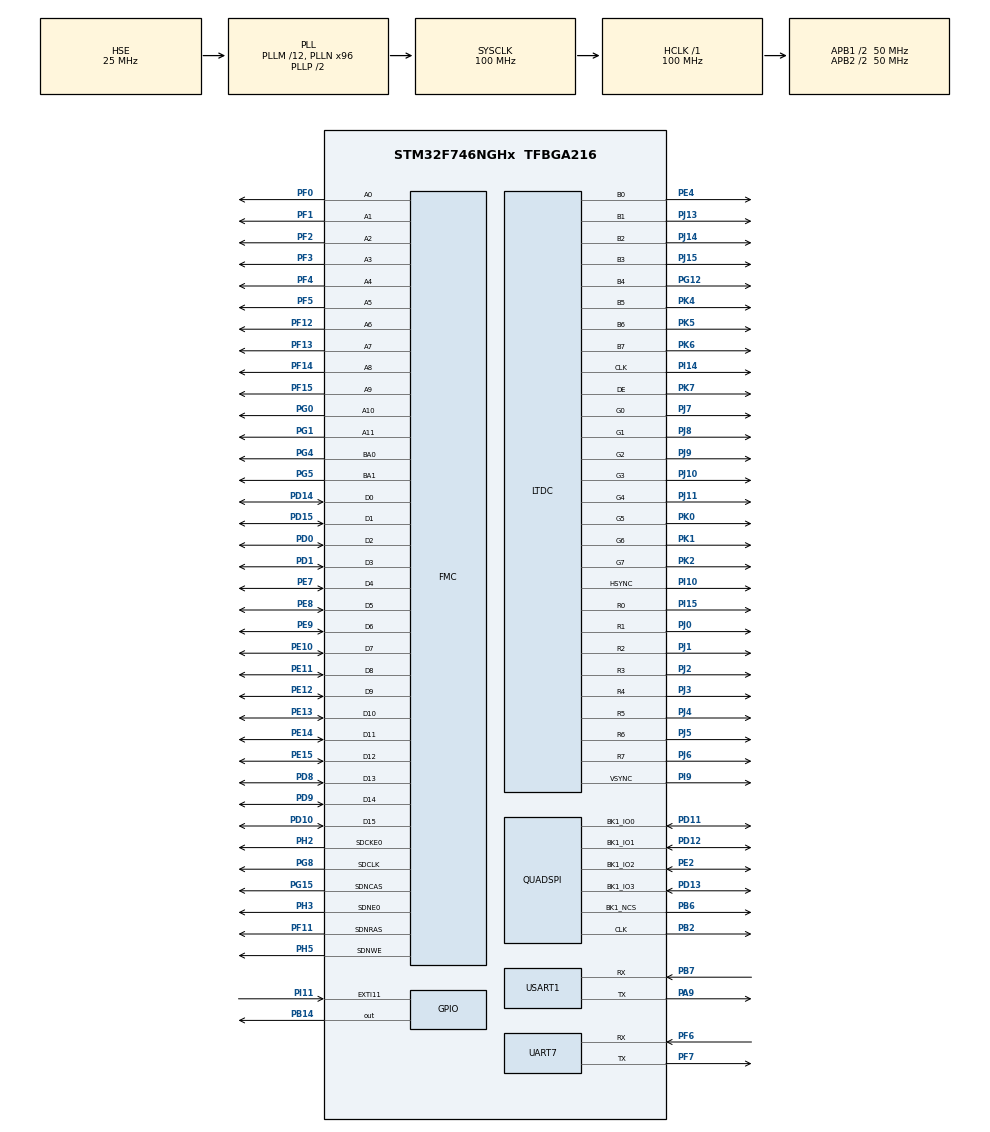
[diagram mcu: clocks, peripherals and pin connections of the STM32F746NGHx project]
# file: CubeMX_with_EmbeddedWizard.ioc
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DMA2D.ColorMode=DMA2D_OUTPUT_RGB565
FMC.CASLatency1=FMC_SDRAM_CAS_LATENCY_3
FMC.ExitSelfRefreshDelay1=7
FMC.LoadToActiveDelay1=2
FMC.RCDDelay1=2
FMC.RPDelay1=2
FMC.RowCycleDelay1=7
FMC.SDClockPeriod1=FMC_SDRAM_CLOCK_PERIOD_2
FMC.SelfRefreshTime1=4
FMC.WriteRecoveryTime1=3
FREERTOS.Queues01=myQueue01,10,uint16_t,0,Dynamic,NULL,NULL
FREERTOS.Tasks01=EwThreadHandle,0,1280,GuiThread,Default,NULL,Dynamic,NULL,NULL;DHT11,0,512,StartTask02,Default,NULL,Dynamic,NULL,NULL
FREERTOS.configTOTAL_HEAP_SIZE=10240
LTDC.ActiveH=272
LTDC.ActiveW=480
LTDC.Alpha_L0=255
LTDC.FBStartAdress_L0=0xC0000000
LTDC.HBP=13
LTDC.HFP=32
LTDC.HSync=41
LTDC.ImageHeight_L0=272
LTDC.ImageWidth_L0=480
LTDC.Layers=0
LTDC.PixelFormat_L0=LTDC_PIXEL_FORMAT_RGB565
LTDC.PixelFormat_L1=LTDC_PIXEL_FORMAT_RGB565
LTDC.VSync=10
LTDC.WindowX1_L0=480
LTDC.WindowY1_L0=272
Mcu.Family=STM32F7
Mcu.Name=STM32F746NGHx
Mcu.Package=TFBGA216
NVIC.DMA2D_IRQn=true\:8\:0\:true\:false\:true\:true\:true\:true
NVIC.EXTI15_10_IRQn=true\:8\:0\:true\:false\:true\:true\:true\:true
NVIC.LTDC_IRQn=true\:8\:0\:true\:false\:true\:true\:true\:true
NVIC.PriorityGroup=NVIC_PRIORITYGROUP_4
NVIC.UART7_IRQn=true\:5\:0\:false\:false\:true\:true\:true\:true
PA9.Mode=Asynchronous
PA9.Signal=USART1_TX
PB14.Signal=GPIO_Output
PB2.Mode=Single Bank 1
PB2.Signal=QUADSPI_CLK
PB6.Mode=Single Bank 1
PB6.Signal=QUADSPI_BK1_NCS
PB7.Mode=Asynchronous
PB7.Signal=USART1_RX
PD0.Signal=FMC_D2_DA2
PD1.Signal=FMC_D3_DA3
PD10.Signal=FMC_D15_DA15
PD11.Mode=Single Bank 1
PD11.Signal=QUADSPI_BK1_IO0
PD12.Mode=Single Bank 1
PD12.Signal=QUADSPI_BK1_IO1
PD13.Mode=Single Bank 1
PD13.Signal=QUADSPI_BK1_IO3
PD14.Signal=FMC_D0_DA0
PD15.Signal=FMC_D1_DA1
PD8.Signal=FMC_D13_DA13
PD9.Signal=FMC_D14_DA14
PE10.Signal=FMC_D7_DA7
PE11.Signal=FMC_D8_DA8
PE12.Signal=FMC_D9_DA9
PE13.Signal=FMC_D10_DA10
PE14.Signal=FMC_D11_DA11
PE15.Signal=FMC_D12_DA12
PE2.Mode=Single Bank 1
PE2.Signal=QUADSPI_BK1_IO2
PE4.GPIO_Speed=GPIO_SPEED_FREQ_VERY_HIGH
PE4.Mode=RGB888
PE4.Signal=LTDC_B0
PE7.Signal=FMC_D4_DA4
PE8.Signal=FMC_D5_DA5
PE9.Signal=FMC_D6_DA6
PF0.Signal=FMC_A0
PF1.Signal=FMC_A1
PF11.Signal=FMC_SDNRAS
PF12.Signal=FMC_A6
PF13.Signal=FMC_A7
PF14.Signal=FMC_A8
PF15.Signal=FMC_A9
PF2.Signal=FMC_A2
PF3.Signal=FMC_A3
PF4.Signal=FMC_A4
PF5.Signal=FMC_A5
PF6.Mode=Asynchronous
PF6.Signal=UART7_RX
PF7.Mode=Asynchronous
PF7.Signal=UART7_TX
PG0.Signal=FMC_A10
PG1.Signal=FMC_A11
PG12.Mode=RGB888
PG12.Signal=LTDC_B4
PG15.Signal=FMC_SDNCAS
PG4.Signal=FMC_A14_BA0
PG5.Signal=FMC_A15_BA1
PG8.Signal=FMC_SDCLK
PH0/OSC_IN.Mode=HSE-External-Oscillator
PH0/OSC_IN.Signal=RCC_OSC_IN
PH1/OSC_OUT.Mode=HSE-External-Oscillator
PH1/OSC_OUT.Signal=RCC_OSC_OUT
PH2.Mode=SdramChipSelect1_1
PH2.Signal=FMC_SDCKE0
PH3.Mode=SdramChipSelect1_1
PH3.Signal=FMC_SDNE0
PH5.Signal=FMC_SDNWE
PI10.Mode=RGB888
PI10.Signal=LTDC_HSYNC
PI11.GPIO_ModeDefaultEXTI=GPIO_MODE_IT_RISING_FALLING
PI11.GPIO_PuPd=GPIO_NOPULL
PI11.Signal=GPXTI11
PI14.Mode=RGB888
PI14.Signal=LTDC_CLK
PI15.Mode=RGB888
PI15.Signal=LTDC_R0
PI9.Mode=RGB888
PI9.Signal=LTDC_VSYNC
PJ0.Mode=RGB888
PJ0.Signal=LTDC_R1
PJ1.Mode=RGB888
PJ1.Signal=LTDC_R2
PJ10.Mode=RGB888
PJ10.Signal=LTDC_G3
PJ11.Mode=RGB888
PJ11.Signal=LTDC_G4
PJ13.Mode=RGB888
PJ13.Signal=LTDC_B1
PJ14.Mode=RGB888
PJ14.Signal=LTDC_B2
PJ15.Mode=RGB888
PJ15.Signal=LTDC_B3
PJ2.Mode=RGB888
PJ2.Signal=LTDC_R3
PJ3.Mode=RGB888
PJ3.Signal=LTDC_R4
PJ4.Mode=RGB888
PJ4.Signal=LTDC_R5
PJ5.Mode=RGB888
PJ5.Signal=LTDC_R6
PJ6.Mode=RGB888
PJ6.Signal=LTDC_R7
PJ7.Mode=RGB888
PJ7.Signal=LTDC_G0
PJ8.Mode=RGB888
PJ8.Signal=LTDC_G1
PJ9.Mode=RGB888
PJ9.Signal=LTDC_G2
PK0.Mode=RGB888
PK0.Signal=LTDC_G5
PK1.Mode=RGB888
PK1.Signal=LTDC_G6
PK2.Mode=RGB888
PK2.Signal=LTDC_G7
PK4.Mode=RGB888
PK4.Signal=LTDC_B5
PK5.Mode=RGB888
PK5.Signal=LTDC_B6
PK6.Mode=RGB888
PK6.Signal=LTDC_B7
PK7.Mode=RGB888
PK7.Signal=LTDC_DE
ProjectManager.HeapSize=0x200
ProjectManager.StackSize=0x400
ProjectManager.TargetToolchain=STM32CubeIDE
RCC.AHBFreq_Value=100000000
RCC.APB1CLKDivider=RCC_HCLK_DIV2
RCC.APB1Freq_Value=50000000
RCC.APB1TimFreq_Value=100000000
RCC.APB2CLKDivider=RCC_HCLK_DIV2
RCC.APB2Freq_Value=50000000
RCC.APB2TimFreq_Value=100000000
RCC.CortexFreq_Value=100000000
RCC.HCLKFreq_Value=100000000
RCC.HSE_VALUE=25000000
RCC.HSI_VALUE=16000000
RCC.LSE_VALUE=32768
RCC.PLL48CLockSelection=RCC_CLK48SOURCE_PLLSAIP
RCC.PLLI2SN=100
RCC.PLLM=12
RCC.PLLN=96
RCC.PLLQ=9
RCC.PLLSAIN=50
RCC.PLLSAIP=RCC_PLLSAIP_DIV8
RCC.PLLSourceVirtual=RCC_PLLSOURCE_HSE
RCC.SDMMCClockSelection=RCC_SDMMC1CLKSOURCE_CLK48
RCC.SYSCLKFreq_VALUE=100000000
RCC.SYSCLKSource=RCC_SYSCLKSOURCE_PLLCLK
RCC.USBFreq_Value=13020833.333333332
RCC.VCOOutputFreq_Value=200000000
SH.FMC_A0.0=FMC_A0,12b-sda1
SH.FMC_A1.0=FMC_A1,12b-sda1
SH.FMC_A10.0=FMC_A10,12b-sda1
SH.FMC_A11.0=FMC_A11,12b-sda1
SH.FMC_A14_BA0.0=FMC_BA0,FourSdramBanks1
SH.FMC_A15_BA1.0=FMC_BA1,FourSdramBanks1
SH.FMC_A2.0=FMC_A2,12b-sda1
SH.FMC_A3.0=FMC_A3,12b-sda1
SH.FMC_A4.0=FMC_A4,12b-sda1
SH.FMC_A5.0=FMC_A5,12b-sda1
SH.FMC_A6.0=FMC_A6,12b-sda1
SH.FMC_A7.0=FMC_A7,12b-sda1
SH.FMC_A8.0=FMC_A8,12b-sda1
SH.FMC_A9.0=FMC_A9,12b-sda1
SH.FMC_D0_DA0.0=FMC_D0,sd-16b-d1
SH.FMC_D10_DA10.0=FMC_D10,sd-16b-d1
SH.FMC_D11_DA11.0=FMC_D11,sd-16b-d1
SH.FMC_D12_DA12.0=FMC_D12,sd-16b-d1
SH.FMC_D13_DA13.0=FMC_D13,sd-16b-d1
SH.FMC_D14_DA14.0=FMC_D14,sd-16b-d1
SH.FMC_D15_DA15.0=FMC_D15,sd-16b-d1
SH.FMC_D1_DA1.0=FMC_D1,sd-16b-d1
SH.FMC_D2_DA2.0=FMC_D2,sd-16b-d1
SH.FMC_D3_DA3.0=FMC_D3,sd-16b-d1
SH.FMC_D4_DA4.0=FMC_D4,sd-16b-d1
SH.FMC_D5_DA5.0=FMC_D5,sd-16b-d1
SH.FMC_D6_DA6.0=FMC_D6,sd-16b-d1
SH.FMC_D7_DA7.0=FMC_D7,sd-16b-d1
SH.FMC_D8_DA8.0=FMC_D8,sd-16b-d1
SH.FMC_D9_DA9.0=FMC_D9,sd-16b-d1
SH.FMC_SDCLK.0=FMC_SDCLK,12b-sda1
SH.FMC_SDNCAS.0=FMC_SDNCAS,12b-sda1
SH.FMC_SDNRAS.0=FMC_SDNRAS,12b-sda1
SH.FMC_SDNWE.0=FMC_SDNWE,12b-sda1
TIM2.Period=3
TIM2.Prescaler=24
USART1.VirtualMode-Asynchronous=VM_ASYNC
VP_DMA2D_VS_DMA2D.Mode=DMA2D_Activate
VP_FREERTOS_VS_CMSIS_V1.Mode=CMSIS_V1
VP_RTC_VS_RTC_Activate.Mode=RTC_Enabled
VP_TIM2_VS_ClockSourceINT.Mode=Internal
board=32F746GDISCOVERY

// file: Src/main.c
#include "main.h"
#include "cmsis_os.h"
#include "DHT11.h"

/* USER CODE BEGIN Includes */
#include "ewmain.h"
#include "ewrte.h"
#include "ew_bsp_console.h"

#include "stm32746g_discovery.h"
#include "stm32746g_discovery_sdram.h"
#include "stm32746g_discovery_qspi.h"

//#include "ModbusRTU.c"
/* USER CODE END Includes */

/* USER CODE BEGIN PTD */
extern float tempDHT;
extern float humidDHT;
float temp;
float humid;
extern unsigned int lux;
/* USER CODE END PTD */

DMA2D_HandleTypeDef hdma2d;

LTDC_HandleTypeDef hltdc;

QSPI_HandleTypeDef hqspi;

RTC_HandleTypeDef hrtc;

TIM_HandleTypeDef htim2;

UART_HandleTypeDef huart7;
UART_HandleTypeDef huart1;

SDRAM_HandleTypeDef hsdram1;

osThreadId EwThreadHandleHandle;
osThreadId DHT11Handle;
osMessageQId myQueue01Handle;

void SystemClock_Config(void);
static void MX_GPIO_Init(void);
static void MX_USART1_UART_Init(void);
static void MX_FMC_Init(void);
static void MX_DMA2D_Init(void);
static void MX_RTC_Init(void);
static void MX_LTDC_Init(void);
static void MX_QUADSPI_Init(void);
static void MX_UART7_Init(void);
static void MX_TIM2_Init(void);
static void EW_SDRAM_Init(void);
static void EW_MPU_Init(void);

void GuiThread(void const * argument);
void StartTask02(void const * argument);

int flag_time = 0;
//void timer2_callBack(TIM_HandleTypeDef *htim){
//	if( htim->Instance == TIM2 ){
//		DHT11_init();
//		temp = tempDHT;
//		humid = humidDHT;
//	}
//}

int main(void)
{

  /* MCU Configuration--------------------------------------------------------*/

  /* Reset of all peripherals, Initializes the Flash interface and the Systick. */
  HAL_Init();

  /* Configure the system clock */
  SystemClock_Config();

  /* USER CODE BEGIN SysInit */
  EW_MPU_Init();
  /* USER CODE END SysInit */

  /* Initialize all configured peripherals */
  MX_GPIO_Init();
  MX_USART1_UART_Init();
  MX_FMC_Init();
  MX_DMA2D_Init();
  MX_RTC_Init();
  MX_LTDC_Init();
  MX_QUADSPI_Init();
  MX_UART7_Init();
  MX_TIM2_Init();
 // DHT11_init();
  /* USER CODE BEGIN 2 */
  EW_SDRAM_Init();
//  HAL_TIM_Base_Start_IT(&htim2);
  /* USER CODE END 2 */

  /* Create the queue(s) */
  /* definition and creation of myQueue01 */
  osMessageQDef(myQueue01, 10, uint16_t);
  myQueue01Handle = osMessageCreate(osMessageQ(myQueue01), NULL);

  /* USER CODE BEGIN RTOS_QUEUES */
  #if EW_USE_FREE_RTOS == 1
  EwPrint( "Create UI thread...                          " );
  /* USER CODE END RTOS_QUEUES */

  /* Create the thread(s) */
  /* definition and creation of EwThreadHandle */
  osThreadDef(EwThreadHandle, GuiThread, osPriorityNormal, 0, 1024);
  EwThreadHandleHandle = osThreadCreate(osThread(EwThreadHandle), NULL);
  /* definition and creation of DHT11 */
  osThreadDef(DHT11, StartTask02, osPriorityNormal, 0, 512);
  DHT11Handle = osThreadCreate(osThread(DHT11), NULL);

  /* USER CODE BEGIN RTOS_THREADS */
  EwPrint( "[OK]\n" );
  #endif
  /* USER CODE END RTOS_THREADS */

   /* definition and creation of DHT11 */

  /* Start scheduler */
  osKernelStart();

  /* We should never get here as control is now taken by the scheduler */

  /* Infinite loop */
  while (1)
  {

    /* USER CODE BEGIN 3 */
  }
  #if EW_USE_FREE_RTOS == 1
  /* de-initialize Embedded Wizard application */
  EwDone();

  return 0;
  #endif
  /* USER CODE END 3 */
}

void SystemClock_Config(void)
{
  RCC_OscInitTypeDef RCC_OscInitStruct = {0};
  RCC_ClkInitTypeDef RCC_ClkInitStruct = {0};
  RCC_PeriphCLKInitTypeDef PeriphClkInitStruct = {0};

  /** Configure the main internal regulator output voltage
  */
  __HAL_RCC_PWR_CLK_ENABLE();
  __HAL_PWR_VOLTAGESCALING_CONFIG(PWR_REGULATOR_VOLTAGE_SCALE3);
  /** Initializes the CPU, AHB and APB busses clocks
  */
  RCC_OscInitStruct.OscillatorType = RCC_OSCILLATORTYPE_LSI|RCC_OSCILLATORTYPE_HSE;
  RCC_OscInitStruct.HSEState = RCC_HSE_ON;
  RCC_OscInitStruct.LSIState = RCC_LSI_ON;
  RCC_OscInitStruct.PLL.PLLState = RCC_PLL_ON;
  RCC_OscInitStruct.PLL.PLLSource = RCC_PLLSOURCE_HSE;
  RCC_OscInitStruct.PLL.PLLM = 12;
  RCC_OscInitStruct.PLL.PLLN = 96;
  RCC_OscInitStruct.PLL.PLLP = RCC_PLLP_DIV2;
  RCC_OscInitStruct.PLL.PLLQ = 9;
  if (HAL_RCC_OscConfig(&RCC_OscInitStruct) != HAL_OK)
  {
    Error_Handler();
  }
  /** Activate the Over-Drive mode
  */
  if (HAL_PWREx_EnableOverDrive() != HAL_OK)
  {
    Error_Handler();
  }
  /** Initializes the CPU, AHB and APB busses clocks
  */
  RCC_ClkInitStruct.ClockType = RCC_CLOCKTYPE_HCLK|RCC_CLOCKTYPE_SYSCLK
                              |RCC_CLOCKTYPE_PCLK1|RCC_CLOCKTYPE_PCLK2;
  RCC_ClkInitStruct.SYSCLKSource = RCC_SYSCLKSOURCE_PLLCLK;
  RCC_ClkInitStruct.AHBCLKDivider = RCC_SYSCLK_DIV1;
  RCC_ClkInitStruct.APB1CLKDivider = RCC_HCLK_DIV2;
  RCC_ClkInitStruct.APB2CLKDivider = RCC_HCLK_DIV2;

  if (HAL_RCC_ClockConfig(&RCC_ClkInitStruct, FLASH_LATENCY_3) != HAL_OK)
  {
    Error_Handler();
  }
  PeriphClkInitStruct.PeriphClockSelection = RCC_PERIPHCLK_LTDC|RCC_PERIPHCLK_RTC
                              |RCC_PERIPHCLK_USART1|RCC_PERIPHCLK_UART7;
  PeriphClkInitStruct.PLLSAI.PLLSAIN = 50;
  PeriphClkInitStruct.PLLSAI.PLLSAIR = 2;
  PeriphClkInitStruct.PLLSAI.PLLSAIQ = 2;
  PeriphClkInitStruct.PLLSAI.PLLSAIP = RCC_PLLSAIP_DIV8;
  PeriphClkInitStruct.PLLSAIDivQ = 1;
  PeriphClkInitStruct.PLLSAIDivR = RCC_PLLSAIDIVR_2;
  PeriphClkInitStruct.RTCClockSelection = RCC_RTCCLKSOURCE_LSI;
  PeriphClkInitStruct.Usart1ClockSelection = RCC_USART1CLKSOURCE_PCLK2;
  PeriphClkInitStruct.Uart7ClockSelection = RCC_UART7CLKSOURCE_PCLK1;
  if (HAL_RCCEx_PeriphCLKConfig(&PeriphClkInitStruct) != HAL_OK)
  {
    Error_Handler();
  }
}

static void MX_DMA2D_Init(void)
{

  hdma2d.Instance = DMA2D;
  hdma2d.Init.Mode = DMA2D_M2M;
  hdma2d.Init.ColorMode = DMA2D_OUTPUT_RGB565;
  hdma2d.Init.OutputOffset = 0;
  hdma2d.LayerCfg[1].InputOffset = 0;
  hdma2d.LayerCfg[1].InputColorMode = DMA2D_INPUT_RGB565;
  hdma2d.LayerCfg[1].AlphaMode = DMA2D_NO_MODIF_ALPHA;
  hdma2d.LayerCfg[1].InputAlpha = 0;
  if (HAL_DMA2D_Init(&hdma2d) != HAL_OK)
  {
    Error_Handler();
  }
  if (HAL_DMA2D_ConfigLayer(&hdma2d, 1) != HAL_OK)
  {
    Error_Handler();
  }

}

static void MX_LTDC_Init(void)
{

  /* USER CODE BEGIN LTDC_Init 0 */
//
  /* USER CODE END LTDC_Init 0 */

  LTDC_LayerCfgTypeDef pLayerCfg = {0};

  /* USER CODE BEGIN LTDC_Init 1 */
//
  /* USER CODE END LTDC_Init 1 */
  hltdc.Instance = LTDC;
  hltdc.Init.HSPolarity = LTDC_HSPOLARITY_AL;
  hltdc.Init.VSPolarity = LTDC_VSPOLARITY_AL;
  hltdc.Init.DEPolarity = LTDC_DEPOLARITY_AL;
  hltdc.Init.PCPolarity = LTDC_PCPOLARITY_IPC;
  hltdc.Init.HorizontalSync = 40;
  hltdc.Init.VerticalSync = 9;
  hltdc.Init.AccumulatedHBP = 53;
  hltdc.Init.AccumulatedVBP = 11;
  hltdc.Init.AccumulatedActiveW = 533;
  hltdc.Init.AccumulatedActiveH = 283;
  hltdc.Init.TotalWidth = 565;
  hltdc.Init.TotalHeigh = 285;
  hltdc.Init.Backcolor.Blue = 0;
  hltdc.Init.Backcolor.Green = 0;
  hltdc.Init.Backcolor.Red = 0;
  if (HAL_LTDC_Init(&hltdc) != HAL_OK)
  {
    Error_Handler();
  }
  pLayerCfg.WindowX0 = 0;
  pLayerCfg.WindowX1 = 480;
  pLayerCfg.WindowY0 = 0;
  pLayerCfg.WindowY1 = 272;
  pLayerCfg.PixelFormat = LTDC_PIXEL_FORMAT_RGB565;
  pLayerCfg.Alpha = 255;
  pLayerCfg.Alpha0 = 0;
  pLayerCfg.BlendingFactor1 = LTDC_BLENDING_FACTOR1_CA;
  pLayerCfg.BlendingFactor2 = LTDC_BLENDING_FACTOR2_CA;
  pLayerCfg.FBStartAdress = 0xC0000000;
  pLayerCfg.ImageWidth = 480;
  pLayerCfg.ImageHeight = 272;
  pLayerCfg.Backcolor.Blue = 0;
  pLayerCfg.Backcolor.Green = 0;
  pLayerCfg.Backcolor.Red = 0;
  if (HAL_LTDC_ConfigLayer(&hltdc, &pLayerCfg, 0) != HAL_OK)
  {
    Error_Handler();
  }
  /* USER CODE BEGIN LTDC_Init 2 */
//
  /* USER CODE END LTDC_Init 2 */

}

static void MX_QUADSPI_Init(void)
{

  /* USER CODE BEGIN QUADSPI_Init 0 */
#if EW_USE_EXTERNAL_FLASH == 1
  /* USER CODE END QUADSPI_Init 0 */

  /* QUADSPI parameter configuration*/
  hqspi.Instance = QUADSPI;
  hqspi.Init.ClockPrescaler = 255;
  hqspi.Init.FifoThreshold = 1;
  hqspi.Init.SampleShifting = QSPI_SAMPLE_SHIFTING_NONE;
  hqspi.Init.FlashSize = 1;
  hqspi.Init.ChipSelectHighTime = QSPI_CS_HIGH_TIME_1_CYCLE;
  hqspi.Init.ClockMode = QSPI_CLOCK_MODE_0;
  hqspi.Init.FlashID = QSPI_FLASH_ID_1;
  hqspi.Init.DualFlash = QSPI_DUALFLASH_DISABLE;
  if (HAL_QSPI_Init(&hqspi) != HAL_OK)
  {
    Error_Handler();
  }
  /* USER CODE BEGIN QUADSPI_Init 2 */

  BSP_QSPI_Init();
  BSP_QSPI_EnableMemoryMappedMode();

  /* configure QSPI: LPTR register with the low-power time out value */
  WRITE_REG( QUADSPI->LPTR, 0xFFF );
#endif
  /* USER CODE END QUADSPI_Init 2 */

}

static void MX_RTC_Init(void)
{

  /** Initialize RTC Only
  */
  hrtc.Instance = RTC;
  hrtc.Init.HourFormat = RTC_HOURFORMAT_24;
  hrtc.Init.AsynchPrediv = 127;
  hrtc.Init.SynchPrediv = 255;
  if (HAL_RTC_Init(&hrtc) != HAL_OK)
  {
    Error_Handler();
  }

}

static void MX_TIM2_Init(void)
{

  TIM_ClockConfigTypeDef sClockSourceConfig = {0};
  TIM_MasterConfigTypeDef sMasterConfig = {0};

  htim2.Instance = TIM2;
  htim2.Init.Prescaler = 24;
  htim2.Init.CounterMode = TIM_COUNTERMODE_UP;
  htim2.Init.Period = 3;
  htim2.Init.ClockDivision = TIM_CLOCKDIVISION_DIV1;
  htim2.Init.AutoReloadPreload = TIM_AUTORELOAD_PRELOAD_DISABLE;
  if (HAL_TIM_Base_Init(&htim2) != HAL_OK)
  {
    Error_Handler();
  }
  sClockSourceConfig.ClockSource = TIM_CLOCKSOURCE_INTERNAL;
  if (HAL_TIM_ConfigClockSource(&htim2, &sClockSourceConfig) != HAL_OK)
  {
    Error_Handler();
  }
  sMasterConfig.MasterOutputTrigger = TIM_TRGO_RESET;
  sMasterConfig.MasterSlaveMode = TIM_MASTERSLAVEMODE_DISABLE;
  if (HAL_TIMEx_MasterConfigSynchronization(&htim2, &sMasterConfig) != HAL_OK)
  {
    Error_Handler();
  }
  /* USER CODE BEGIN TIM2_Init 2 */
 // flag_time = 1;
//  __HAL_TIM_CLEAR_FLAG(&htim2, TIM_SR_UIF);
//  HAL_TIM_Base_Start_IT(&htim2);
  /* USER CODE END TIM2_Init 2 */

}

static void MX_UART7_Init(void)
{

  huart7.Instance = UART7;
  huart7.Init.BaudRate = 115200;
  huart7.Init.WordLength = UART_WORDLENGTH_8B;
  huart7.Init.StopBits = UART_STOPBITS_1;
  huart7.Init.Parity = UART_PARITY_NONE;
  huart7.Init.Mode = UART_MODE_TX_RX;
  huart7.Init.HwFlowCtl = UART_HWCONTROL_NONE;
  huart7.Init.OverSampling = UART_OVERSAMPLING_16;
  huart7.Init.OneBitSampling = UART_ONE_BIT_SAMPLE_DISABLE;
  huart7.AdvancedInit.AdvFeatureInit = UART_ADVFEATURE_NO_INIT;
  if (HAL_UART_Init(&huart7) != HAL_OK)
  {
    Error_Handler();
  }

}

static void MX_USART1_UART_Init(void)
{

  huart1.Instance = USART1;
  huart1.Init.BaudRate = 115200;
  huart1.Init.WordLength = UART_WORDLENGTH_8B;
  huart1.Init.StopBits = UART_STOPBITS_1;
  huart1.Init.Parity = UART_PARITY_NONE;
  huart1.Init.Mode = UART_MODE_TX_RX;
  huart1.Init.HwFlowCtl = UART_HWCONTROL_NONE;
  huart1.Init.OverSampling = UART_OVERSAMPLING_16;
  huart1.Init.OneBitSampling = UART_ONE_BIT_SAMPLE_DISABLE;
  huart1.AdvancedInit.AdvFeatureInit = UART_ADVFEATURE_NO_INIT;
  if (HAL_UART_Init(&huart1) != HAL_OK)
  {
    Error_Handler();
  }

}

/* FMC initialization function */
static void MX_FMC_Init(void)
{

  FMC_SDRAM_TimingTypeDef SdramTiming = {0};

  /** Perform the SDRAM1 memory initialization sequence
  */
  hsdram1.Instance = FMC_SDRAM_DEVICE;
  /* hsdram1.Init */
  hsdram1.Init.SDBank = FMC_SDRAM_BANK1;
  hsdram1.Init.ColumnBitsNumber = FMC_SDRAM_COLUMN_BITS_NUM_8;
  hsdram1.Init.RowBitsNumber = FMC_SDRAM_ROW_BITS_NUM_12;
  hsdram1.Init.MemoryDataWidth = FMC_SDRAM_MEM_BUS_WIDTH_16;
  hsdram1.Init.InternalBankNumber = FMC_SDRAM_INTERN_BANKS_NUM_4;
  hsdram1.Init.CASLatency = FMC_SDRAM_CAS_LATENCY_3;
  hsdram1.Init.WriteProtection = FMC_SDRAM_WRITE_PROTECTION_DISABLE;
  hsdram1.Init.SDClockPeriod = FMC_SDRAM_CLOCK_PERIOD_2;
  hsdram1.Init.ReadBurst = FMC_SDRAM_RBURST_DISABLE;
  hsdram1.Init.ReadPipeDelay = FMC_SDRAM_RPIPE_DELAY_0;
  /* SdramTiming */
  SdramTiming.LoadToActiveDelay = 2;
  SdramTiming.ExitSelfRefreshDelay = 7;
  SdramTiming.SelfRefreshTime = 4;
  SdramTiming.RowCycleDelay = 7;
  SdramTiming.WriteRecoveryTime = 3;
  SdramTiming.RPDelay = 2;
  SdramTiming.RCDDelay = 2;

  if (HAL_SDRAM_Init(&hsdram1, &SdramTiming) != HAL_OK)
  {
    Error_Handler( );
  }

}

static void MX_GPIO_Init(void)
{
  GPIO_InitTypeDef GPIO_InitStruct = {0};

  /* GPIO Ports Clock Enable */
  __HAL_RCC_GPIOE_CLK_ENABLE();
  __HAL_RCC_GPIOB_CLK_ENABLE();
  __HAL_RCC_GPIOG_CLK_ENABLE();
  __HAL_RCC_GPIOJ_CLK_ENABLE();
  __HAL_RCC_GPIOD_CLK_ENABLE();
  __HAL_RCC_GPIOK_CLK_ENABLE();
  __HAL_RCC_GPIOF_CLK_ENABLE();
  __HAL_RCC_GPIOI_CLK_ENABLE();
  __HAL_RCC_GPIOA_CLK_ENABLE();
  __HAL_RCC_GPIOH_CLK_ENABLE();

  /*Configure GPIO pin Output Level */
  HAL_GPIO_WritePin(GPIOB, GPIO_PIN_14, GPIO_PIN_RESET);

  /*Configure GPIO pin : PI11 */
  GPIO_InitStruct.Pin = GPIO_PIN_11;
  GPIO_InitStruct.Mode = GPIO_MODE_IT_RISING_FALLING;
  GPIO_InitStruct.Pull = GPIO_NOPULL;
  HAL_GPIO_Init(GPIOI, &GPIO_InitStruct);

  /*Configure GPIO pin : PB14 */
  GPIO_InitStruct.Pin = GPIO_PIN_14;
  GPIO_InitStruct.Mode = GPIO_MODE_OUTPUT_PP;
  GPIO_InitStruct.Pull = GPIO_NOPULL;
  GPIO_InitStruct.Speed = GPIO_SPEED_FREQ_LOW;
  HAL_GPIO_Init(GPIOB, &GPIO_InitStruct);

  /* EXTI interrupt init*/
  HAL_NVIC_SetPriority(EXTI15_10_IRQn, 8, 0);
  HAL_NVIC_EnableIRQ(EXTI15_10_IRQn);

}

/* USER CODE BEGIN 4 */
/**
  * @brief Core Configuration
  * @param None
  * @retval None
  */
static void EW_SDRAM_Init(void)
{
	  /* Disable FMC bank1 (0x6000 0000 - 0x6FFF FFFF), since it is not used.
	     This setting avoids unnedded speculative access to the first FMC bank.
	     See also STM Application Note AN4861 */
	  FMC_Bank1->BTCR[0] = 0x000030D2;

	  /* Enable I-Cache */
	  SCB_EnableICache();

	  /* Enable D-Cache */
	  SCB_EnableDCache();

	  BSP_SDRAM_Init();
}

static void EW_MPU_Init(void)
{
	  MPU_Region_InitTypeDef MPU_InitStruct;

	  /* Disable the MPU */
	  HAL_MPU_Disable();

	  /* Configure the MPU attributes as WT for SRAM */
	  MPU_InitStruct.Enable           = MPU_REGION_ENABLE;
	  MPU_InitStruct.BaseAddress      = 0x20010000;
	  MPU_InitStruct.Size             = MPU_REGION_SIZE_256KB;
	  MPU_InitStruct.AccessPermission = MPU_REGION_FULL_ACCESS;
	  MPU_InitStruct.IsBufferable     = MPU_ACCESS_NOT_BUFFERABLE;
	  MPU_InitStruct.IsCacheable      = MPU_ACCESS_CACHEABLE;
	  MPU_InitStruct.IsShareable      = MPU_ACCESS_SHAREABLE;
	  MPU_InitStruct.Number           = MPU_REGION_NUMBER0;
	  MPU_InitStruct.TypeExtField     = MPU_TEX_LEVEL0;
	  MPU_InitStruct.SubRegionDisable = 0x00;
	  MPU_InitStruct.DisableExec      = MPU_INSTRUCTION_ACCESS_ENABLE;
	  HAL_MPU_ConfigRegion(&MPU_InitStruct);

	  /* Configure the MPU attributes for Quad-SPI area to strongly ordered
	     This setting is essentially needed to avoid MCU blockings!
	     See also STM Application Note AN4861 */
	  MPU_InitStruct.Enable           = MPU_REGION_ENABLE;
	  MPU_InitStruct.Number           = MPU_REGION_NUMBER2;
	  MPU_InitStruct.BaseAddress      = 0x90000000;
	  MPU_InitStruct.Size             = MPU_REGION_SIZE_256MB;
	  MPU_InitStruct.SubRegionDisable = 0x0;
	  MPU_InitStruct.TypeExtField     = MPU_TEX_LEVEL0;
	  MPU_InitStruct.AccessPermission = MPU_REGION_NO_ACCESS;
	  MPU_InitStruct.DisableExec      = MPU_INSTRUCTION_ACCESS_DISABLE;
	  MPU_InitStruct.IsShareable      = MPU_ACCESS_SHAREABLE;
	  MPU_InitStruct.IsCacheable      = MPU_ACCESS_NOT_CACHEABLE;
	  MPU_InitStruct.IsBufferable     = MPU_ACCESS_NOT_BUFFERABLE;
	  HAL_MPU_ConfigRegion(&MPU_InitStruct);

	  /* Configure the MPU attributes for the QSPI 16MB to normal memory Cacheable, must reflect the real memory size */
	  MPU_InitStruct.Enable           = MPU_REGION_ENABLE;
	  MPU_InitStruct.Number           = MPU_REGION_NUMBER3;
	  MPU_InitStruct.BaseAddress      = 0x90000000;
	  MPU_InitStruct.Size             = MPU_REGION_SIZE_16MB; // Set region size according to the QSPI memory size
	  MPU_InitStruct.SubRegionDisable = 0x0;
	  MPU_InitStruct.TypeExtField     = MPU_TEX_LEVEL0;
	  MPU_InitStruct.AccessPermission = MPU_REGION_FULL_ACCESS;
	  MPU_InitStruct.DisableExec      = MPU_INSTRUCTION_ACCESS_DISABLE;
	  MPU_InitStruct.IsShareable      = MPU_ACCESS_SHAREABLE;
	  MPU_InitStruct.IsCacheable      = MPU_ACCESS_CACHEABLE;
	  MPU_InitStruct.IsBufferable     = MPU_ACCESS_NOT_BUFFERABLE;
	  HAL_MPU_ConfigRegion(&MPU_InitStruct);

	  /* Configure the MPU attributes for SDRAM_Banks area to strongly ordered
	     This setting is essentially needed to avoid MCU blockings!
	     See also STM Application Note AN4861 */
	  MPU_InitStruct.Enable           = MPU_REGION_ENABLE;
	  MPU_InitStruct.Number           = MPU_REGION_NUMBER4;
	  MPU_InitStruct.BaseAddress      = 0xC0000000;
	  MPU_InitStruct.Size             = MPU_REGION_SIZE_512MB;
	  MPU_InitStruct.SubRegionDisable = 0x0;
	  MPU_InitStruct.TypeExtField     = MPU_TEX_LEVEL0;
	  MPU_InitStruct.AccessPermission = MPU_REGION_NO_ACCESS;
	  MPU_InitStruct.DisableExec      = MPU_INSTRUCTION_ACCESS_DISABLE;
	  MPU_InitStruct.IsShareable      = MPU_ACCESS_SHAREABLE;
	  MPU_InitStruct.IsCacheable      = MPU_ACCESS_NOT_CACHEABLE;
	  MPU_InitStruct.IsBufferable     = MPU_ACCESS_NOT_BUFFERABLE;
	  HAL_MPU_ConfigRegion(&MPU_InitStruct);

	  /* Configure the MPU attributes for SDRAM 8MB to normal memory Cacheable */
	  MPU_InitStruct.Enable           = MPU_REGION_ENABLE;
	  MPU_InitStruct.Number           = MPU_REGION_NUMBER5;
	  MPU_InitStruct.BaseAddress      = 0xC0000000;
	  MPU_InitStruct.Size             = MPU_REGION_SIZE_8MB;
	  MPU_InitStruct.SubRegionDisable = 0x0;
	  MPU_InitStruct.TypeExtField     = MPU_TEX_LEVEL0;
	  MPU_InitStruct.AccessPermission = MPU_REGION_FULL_ACCESS;
	  MPU_InitStruct.DisableExec      = MPU_INSTRUCTION_ACCESS_ENABLE;
	  MPU_InitStruct.IsShareable      = MPU_ACCESS_SHAREABLE;
	  MPU_InitStruct.IsCacheable      = MPU_ACCESS_CACHEABLE;
	  MPU_InitStruct.IsBufferable     = MPU_ACCESS_NOT_BUFFERABLE;
	  HAL_MPU_ConfigRegion(&MPU_InitStruct);

	  /* Enable the MPU */
	  HAL_MPU_Enable(MPU_PRIVILEGED_DEFAULT);
}

/* USER CODE END 4 */

void GuiThread(void const * argument)
{
  /* USER CODE BEGIN 5 */

  /* initialize Embedded Wizard application */
  if ( EwInit() == 0 )
	return;

  EwPrintSystemInfo();

  /* process the Embedded Wizard main loop */
  while( EwProcess())
  ;

  /* de-initialize Embedded Wizard application */
  EwDone();

  /* USER CODE END 5 */
}

void StartTask02(void const * argument)
{
  /* USER CODE BEGIN StartTask02 */
  /* Infinite loop */
  for(;;)
  {
	DHT11_init();
	temp = tempDHT;
	humid = humidDHT;
    osDelay(3000);
  }
  /* USER CODE END StartTask02 */
}

void Error_Handler(void)
{
}

/************************ (C) COPYRIGHT STMicroelectronics *****END OF FILE****/

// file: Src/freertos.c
/* USER CODE BEGIN Header */
/**
  ******************************************************************************
  * File Name          : freertos.c
  * Description        : Code for freertos applications
  ******************************************************************************
  * This notice applies to any and all portions of this file
  * that are not between comment pairs USER CODE BEGIN and
  * USER CODE END. Other portions of this file, whether
  * inserted by the user or by software development tools
  * are owned by their respective copyright owners.
  *
  * Copyright (c) 2019 STMicroelectronics International N.V.
  * All rights reserved.
  *
  * Redistribution and use in source and binary forms, with or without
  * modification, are permitted, provided that the following conditions are met:
  *
  * 1. Redistribution of source code must retain the above copyright notice,
  *    this list of conditions and the following disclaimer.
  * 2. Redistributions in binary form must reproduce the above copyright notice,
  *    this list of conditions and the following disclaimer in the documentation
  *    and/or other materials provided with the distribution.
  * 3. Neither the name of STMicroelectronics nor the names of other
  *    contributors to this software may be used to endorse or promote products
  *    derived from this software without specific written permission.
  * 4. This software, including modifications and/or derivative works of this
  *    software, must execute solely and exclusively on microcontroller or
  *    microprocessor devices manufactured by or for STMicroelectronics.
  * 5. Redistribution and use of this software other than as permitted under
  *    this license is void and will automatically terminate your rights under
  *    this license.
  *
  * THIS SOFTWARE IS PROVIDED BY STMICROELECTRONICS AND CONTRIBUTORS "AS IS"
  * AND ANY EXPRESS, IMPLIED OR STATUTORY WARRANTIES, INCLUDING, BUT NOT
  * LIMITED TO, THE IMPLIED WARRANTIES OF MERCHANTABILITY, FITNESS FOR A
  * PARTICULAR PURPOSE AND NON-INFRINGEMENT OF THIRD PARTY INTELLECTUAL PROPERTY
  * RIGHTS ARE DISCLAIMED TO THE FULLEST EXTENT PERMITTED BY LAW. IN NO EVENT
  * SHALL STMICROELECTRONICS OR CONTRIBUTORS BE LIABLE FOR ANY DIRECT, INDIRECT,
  * INCIDENTAL, SPECIAL, EXEMPLARY, OR CONSEQUENTIAL DAMAGES (INCLUDING, BUT NOT
  * LIMITED TO, PROCUREMENT OF SUBSTITUTE GOODS OR SERVICES; LOSS OF USE, DATA,
  * OR PROFITS; OR BUSINESS INTERRUPTION) HOWEVER CAUSED AND ON ANY THEORY OF
  * LIABILITY, WHETHER IN CONTRACT, STRICT LIABILITY, OR TORT (INCLUDING
  * NEGLIGENCE OR OTHERWISE) ARISING IN ANY WAY OUT OF THE USE OF THIS SOFTWARE,
  * EVEN IF ADVISED OF THE POSSIBILITY OF SUCH DAMAGE.
  *
  ******************************************************************************
  */
/* USER CODE END Header */

#include "FreeRTOS.h"
#include "task.h"
#include "main.h"

/* GetIdleTaskMemory prototype (linked to static allocation support) */
void vApplicationGetIdleTaskMemory( StaticTask_t **ppxIdleTaskTCBBuffer, StackType_t **ppxIdleTaskStackBuffer, uint32_t *pulIdleTaskStackSize );

/* USER CODE BEGIN GET_IDLE_TASK_MEMORY */
static StaticTask_t xIdleTaskTCBBuffer;
static StackType_t xIdleStack[configMINIMAL_STACK_SIZE];

void vApplicationGetIdleTaskMemory( StaticTask_t **ppxIdleTaskTCBBuffer, StackType_t **ppxIdleTaskStackBuffer, uint32_t *pulIdleTaskStackSize )
{
  *ppxIdleTaskTCBBuffer = &xIdleTaskTCBBuffer;
  *ppxIdleTaskStackBuffer = &xIdleStack[0];
  *pulIdleTaskStackSize = configMINIMAL_STACK_SIZE;
  /* place for user code */
}
/* USER CODE END GET_IDLE_TASK_MEMORY */

/************************ (C) COPYRIGHT STMicroelectronics *****END OF FILE****/
